NS_ :

BS_:

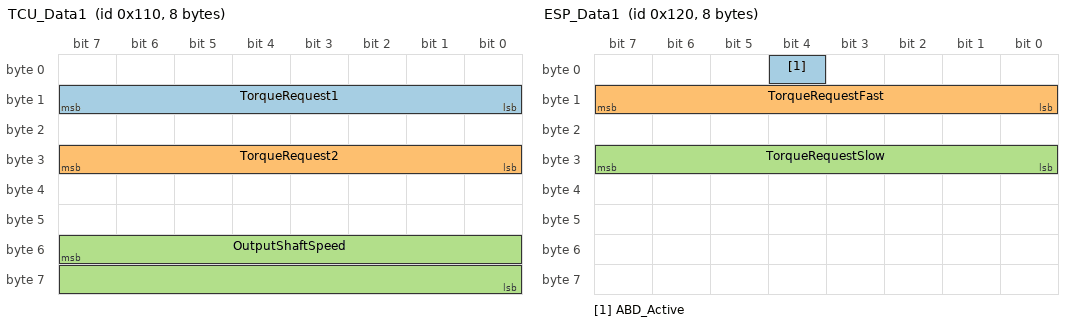
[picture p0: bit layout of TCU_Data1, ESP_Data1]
BO_ 272 TCU_Data1: 8 TCU
 SG_ TorqueRequest1 : 15|8@0+ (1,0) [0|255] ""  ABS,ESP,ECU
 SG_ TorqueRequest2 : 31|8@0+ (1,0) [0|255] ""  ABS,ESP,ECU
 SG_ OutputShaftSpeed : 55|16@0+ (1,0) [0|65535] "rpm"  ABS,ESP,ECU

BO_ 288 ESP_Data1: 8 ESP
 SG_ ABD_Active : 4|1@0+ (1,0) [0|1] "yes/no"  ECU,TCU
 SG_ TorqueRequestFast : 15|8@0+ (1,0) [0|255] ""  ECU,TCU
 SG_ TorqueRequestSlow : 31|8@0+ (1,0) [0|255] ""  ECU,TCU

BO_ 384 SAS_Data: 8 SAS
 SG_ SteeringAngle : 0|16@1- (0.1,0) [-3276.8|3276.7] "yes/no"  ECU,TCU
 SG_ SteeringSpeed : 16|8@1+ (1,0) [0|255] ""  ECU,TCU

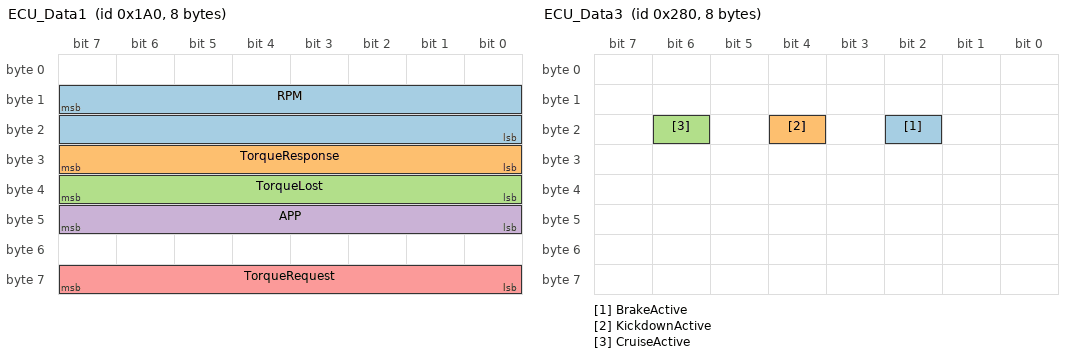
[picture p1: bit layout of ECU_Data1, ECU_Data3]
BO_ 416 ECU_Data1: 8 ECU
 SG_ RPM : 15|16@0+ (1,0) [0|65535] "rpm"  ABS,ESP,TCU
 SG_ TorqueResponse : 31|8@0+ (1,0) [0|255] ""  ABS,ESP,TCU
 SG_ TorqueLost : 39|8@0+ (1,0) [0|255] ""  ABS,ESP,TCU
 SG_ APP : 47|8@0+ (1,0) [0|102] ""  ABS,ESP,TCU
 SG_ TorqueRequest : 63|8@0+ (1,0) [0|255] ""  ABS,ESP,TCU

BO_ 448 ECU_Data2: 8 ECU
 SG_ TPS : 23|8@0+ (1,0) [0|100] ""  ABS,ESP,TCU

BO_ 640 ECU_Data3: 8 ECU
 SG_ BrakeActive : 18|1@0+ (1,0) [0|1] "yes/no"  ABS,ESP,TCU
 SG_ KickdownActive : 20|1@0+ (1,0) [0|1] "yes/no"  ABS,ESP,TCU
 SG_ CruiseActive : 22|1@0+ (1,0) [0|1] "yes/no"  ABS,ESP,TCU

BO_ 736 TCU_Data2: 8 TCU
 SG_ TOT : 31|8@0- (1,-40) [-40|215] ""  ECU
 SG_ InputShaftSpeed : 47|16@0+ (1,0) [0|65535] "rpm"  ECU

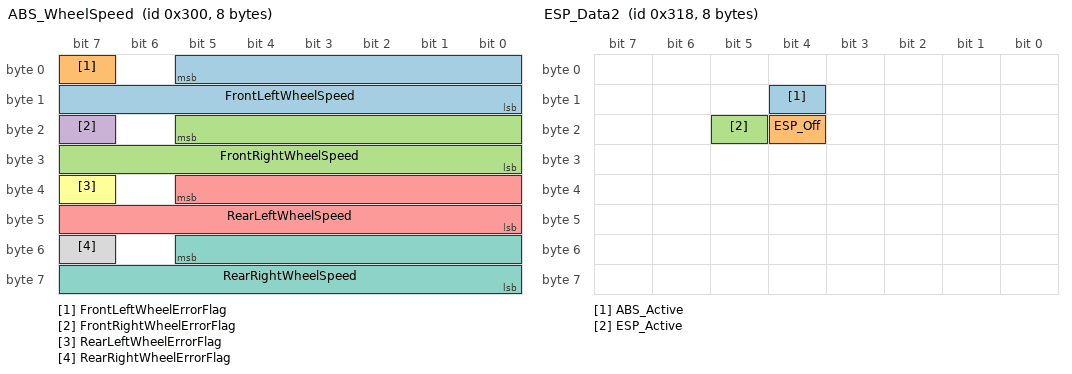
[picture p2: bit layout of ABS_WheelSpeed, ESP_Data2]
BO_ 768 ABS_WheelSpeed: 8 ABS
 SG_ FrontLeftWheelSpeed : 5|14@0+ (0.112,0) [0|255] "km/h"  ECU,TCU
 SG_ FrontLeftWheelErrorFlag : 7|1@0+ (1,0) [0|1] ""  ECU,TCU
 SG_ FrontRightWheelSpeed : 21|14@0+ (0.112,0) [0|255] "km/h"  ECU,TCU
 SG_ FrontRightWheelErrorFlag : 23|1@0+ (1,0) [0|1] ""  ECU,TCU
 SG_ RearLeftWheelSpeed : 37|14@0+ (0.112,0) [0|255] "km/h"  ECU,TCU
 SG_ RearLeftWheelErrorFlag : 39|1@0+ (1,0) [0|1] ""  ECU,TCU
 SG_ RearRightWheelSpeed : 53|14@0+ (0.112,0) [0|255] "km/h"  ECU,TCU
 SG_ RearRightWheelErrorFlag : 55|1@0+ (1,0) [0|1] ""  ECU,TCU

BO_ 792 ESP_Data2: 8 ESP
 SG_ ABS_Active : 12|1@0+ (1,0) [0|1] "yes/no"  ECU,TCU
 SG_ ESP_Off : 20|1@0+ (1,0) [0|1] "yes/no"  ECU,TCU
 SG_ ESP_Active : 21|1@0+ (1,0) [0|1] "yes/no"  ECU,TCU

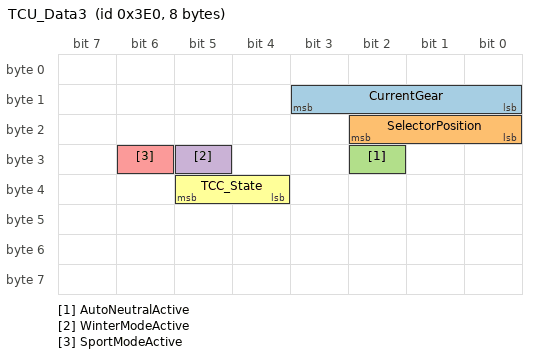
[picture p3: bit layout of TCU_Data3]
BO_ 992 TCU_Data3: 8 TCU
 SG_ CurrentGear : 11|4@0+ (1,0) [0|15] ""  ECU
 SG_ SelectorPosition : 18|3@0+ (1,0) [0|7] ""  ECU
 SG_ AutoNeutralActive : 26|1@0+ (1,0) [0|1] "yes/no"  ECU
 SG_ WinterModeActive : 29|1@0+ (1,0) [0|1] "yes/no"  ECU
 SG_ SportModeActive : 30|1@0+ (1,0) [0|1] "yes/no"  ECU
 SG_ TCC_State : 37|2@0+ (1,0) [0|2] ""  ECU

BO_ 1472 ECU_Data4: 8 ECU
 SG_ ECT : 15|8@0- (1,-40) [-40|215] ""  TCU
 SG_ IAT : 47|8@0- (1,-40) [-40|215] ""  TCU

CM_ "AUTOGENERATED FILE, DO NOT EDIT";

CM_ "Imported file _comma.dbc starts here";
CM_ "Imported file _honda_common.dbc starts here";
CM_ SG_ 304 "Seems to be platform-agnostic";
CM_ SG_ 316 "Should exist on Nidec";
CM_ SG_ 420 BRAKE_HOLD_RELATED "On when Brake Hold engaged";
CM_ SG_ 490 LONG_ACCEL "wheel speed derivative, noisy and zero snapping";
CM_ SG_ 773 PASS_AIRBAG_ON "Might just be indicator light";
CM_ SG_ 773 PASS_AIRBAG_OFF "Might just be indicator light";
CM_ SG_ 780 CRUISE_SPEED "255 = no speed";
CM_ SG_ 780 PCM_SPEED "Used by Nidec";
CM_ SG_ 780 PCM_GAS "Used by Nidec";
CM_ SG_ 804 CRUISE_SPEED_PCM "255 = no speed";

CM_ "Imported file _nidec_common.dbc starts here";
CM_ SG_ 506 AEB_REQ_1 "set for duration of suspected AEB event";
CM_ SG_ 506 COMPUTER_BRAKE_ALT "Used by dual-can Nidec";
CM_ SG_ 506 BRAKE_PUMP_REQUEST_ALT "Used by dual-can Nidec";
CM_ SG_ 829 BEEP "beeps are pleasant, chimes are for warnngs etc...";

CM_ "Imported file _steering_sensors_b.dbc starts here";
CM_ "honda_odyssey_exl_2018.dbc starts here";

CM_ SG_ 419 GEAR "10 = reverse, 11 = transition";
CM_ SG_ 780 CRUISE_SPEED "255 = no speed";
CM_ SG_ 806 REVERSE_LIGHT "Might be reverse gear selected and not the lights";

VAL_ 1228 PROPILOT_NA_MSGS 0 "NO_MSG" 1 "NA_FRONT_CAMERA_IMPARED" 2 "STEERING_ASSIST_ON_STANDBY" 3 "NA_PARKING_ASSIST_ENABLED" 4 "STEER_ASSIST_CURRENTLY_NA" 5 "NA_BAD_WEATHER" 6 "NA_PARK_BRAKE_ON" 7 "NA_SEATBELT_NOT_FASTENED" ;
VAL_ 1228 BOTTOM_MSG 0 "OK_STEER_ASSIST_SETTINGS" 1 "NO_MSG" 2 "PRESS_SET_TO_SET_SPEED" 3 "PRESS_RES_SET_TO_CHANGE_SPEED" 4 "PRESS_RES_TO_RESTART" 5 "NO_MSG" 6 "CRUISE_NOT_AVAIL" 7 "NO_MSG" ;
VAL_ 689 FOLLOW_DISTANCE 0 "NO_FOLLOW_DISTANCE" 1 "FOLLOW_DISTANCE_1" 2 "FOLLOW_DISTANCE_2" 3 "FOLLOW_DISANCE_3" ;
VAL_ 689 AUDIBLE_TONE 0 "NO_TONE" 1 "CONT" 2 "FAST_BEEP_CONT" 3 "TRIPLE_FAST_BEEP_CONT" 4 "SLOW_BEEP_CONT" 5 "QUAD_SLOW_BEEP_CONT" 6 "SINGLE_BEEP_ONCE" 7 "DOUBLE_BEEP_ONCE" ;
VAL_ 689 SMALL_STEERING_WHEEL_ICON 0 "NO_ICON" 1 "GRAY_ICON" 2 "GRAY_ICON_FLASHING" 3 "GREEN_ICON" 4 "GREEN_ICON_FLASHING" 5 "RED_ICON" 6 "RED_ICON_FLASHING" 7 "YELLOW_ICON" ;
VAL_ 689 LARGE_STEERING_WHEEL_ICON 0 "NO_STEERINGWHEEL" 1 "GRAY_STEERINGWHEEL" 2 "GREEN_STEERINGWHEEL" 3 "GREEN_STEERINGWHEEL_FLASHING" ;
